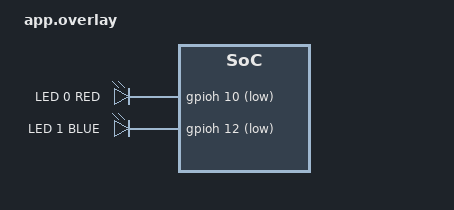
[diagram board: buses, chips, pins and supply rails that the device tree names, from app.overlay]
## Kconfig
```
menuconfig LED_SUBSYSTEM
    bool "LED Subsystem"


    if LED_SUBSYSTEM

        choice
            prompt "LED blink sleep time"
            default BLINK_SLEEP_500MS
            config BLINK_SLEEP_100MS
                bool "Fast (100ms)"
            config BLINK_SLEEP_500MS
                bool "Medium (500ms)"
            config BLINK_SLEEP_2000MS
                bool "Slow (2s)"
        endchoice

        config APP_HEARTBEAT_PERIOD_MS
            int
            default 500 if BLINK_SLEEP_500MS
            default 100 if BLINK_SLEEP_100MS
            default 2000 if BLINK_SLEEP_2000MS
            default 0

        menuconfig LED_ADVANCED
            bool "Advanced LED settings"
            if LED_ADVANCED
                config LED_BRIGHTNESS
                    int "LED brightness (0-100)"
                    default 100
                    range 0 100
                config LED_FADE_DURATION_MS
                    int "Fade duration (ms)"
                    default 500
                    range 0 5000
            endif
        menu "Expert settings"
            visible if LED_ADVANCED
            config LED_DEBUG
                bool "Enable LED debugging"
            config CUSTOM_BLINK_PATTERN
                bool "Custom blink pattern"

endmenu

endif   # LED_SUBSYSTEM

source "Kconfig.zephyr"
```

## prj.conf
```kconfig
CONFIG_GPIO=y
CONFIG_LOG=y
CONFIG_DEBUG_OPTIMIZATIONS=y
```

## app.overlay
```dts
/ {
    /* Map the alias to your specific LED so DT_ALIAS(led0) works in C */
    aliases {
        led0 = &red_led;
        led1 = &blue_led;
    };

    leds {
        /* Required to load the GPIO LED driver */
        compatible = "gpio-leds"; 
        
        red_led: led_0 {
            label = "LED 0 RED";
            /* Try ACTIVE_LOW if HIGH keeps the LED permanently on */
            gpios = <&gpioh 10 GPIO_ACTIVE_LOW>; 
        };
        
        blue_led: led_1 {
            label = "LED 1 BLUE";
            gpios = <&gpioh 12 GPIO_ACTIVE_LOW>;
        };
    };
};
```

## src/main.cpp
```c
#include <zephyr/drivers/gpio.h>
#include <zephyr/kernel.h>
#include <zephyr/logging/log.h>

/* The devicetree node identifiers for the aliases */
#define LED_NODE_RED DT_ALIAS(led0)
#define LED_NODE_BLUE DT_ALIAS(led1)

static const struct gpio_dt_spec led_red = GPIO_DT_SPEC_GET(LED_NODE_RED, gpios);
static const struct gpio_dt_spec led_blue = GPIO_DT_SPEC_GET(LED_NODE_BLUE, gpios);

LOG_MODULE_REGISTER(main, LOG_LEVEL_INF);

int main(void)
{
    bool is_red_turn = true;

    /* Check if devices are ready */
    if (!gpio_is_ready_dt(&led_red)) {
        LOG_ERR("Red LED device not ready");
        return 0;
    }
    if (!gpio_is_ready_dt(&led_blue)) {
        LOG_ERR("Blue LED device not ready");
        return 0;
    }

    /* Configure both as outputs, initially OFF (INACTIVE) */
    if (gpio_pin_configure_dt(&led_red, GPIO_OUTPUT_INACTIVE) < 0) return 0;
    if (gpio_pin_configure_dt(&led_blue, GPIO_OUTPUT_INACTIVE) < 0) return 0;

    LOG_INF("Starting alternating blink loop...");

    while (1) {
        if (is_red_turn) {
            /* Set Red ACTIVE (1) and Blue INACTIVE (0) */
            gpio_pin_set_dt(&led_red, 1);
            gpio_pin_set_dt(&led_blue, 0);
            LOG_INF("LED state: RED is ON, BLUE is OFF");
        } else {
            /* Set Red INACTIVE (0) and Blue ACTIVE (1) */
            gpio_pin_set_dt(&led_red, 0);
            gpio_pin_set_dt(&led_blue, 1);
            LOG_INF("LED state: RED is OFF, BLUE is ON");
        }

        /* Swap turns for the next loop iteration */
        is_red_turn = !is_red_turn;
        
        k_msleep(CONFIG_APP_HEARTBEAT_PERIOD_MS);
    }
    return 0;
}
```
